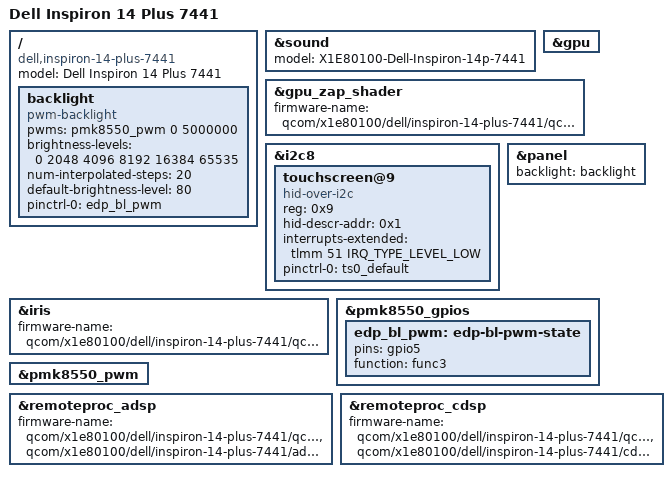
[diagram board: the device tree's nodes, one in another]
// SPDX-License-Identifier: BSD-3-Clause
/*
 * Copyright (c) 2025 Val Packett <val@packett.cool>
 */
/dts-v1/;

#include "hamoa.dtsi"
#include "x1-dell-thena.dtsi"

/ {
	model = "Dell Inspiron 14 Plus 7441";
	compatible = "dell,inspiron-14-plus-7441", "qcom,x1e80100";

	backlight: backlight {
		compatible = "pwm-backlight";
		pwms = <&pmk8550_pwm 0 5000000>;

		brightness-levels = <0 2048 4096 8192 16384 65535>;
		num-interpolated-steps = <20>;
		default-brightness-level = <80>;

		pinctrl-0 = <&edp_bl_pwm>;
		pinctrl-names = "default";
	};
};

&sound {
	model = "X1E80100-Dell-Inspiron-14p-7441";
};

&gpu {
	status = "okay";
};

&gpu_zap_shader {
	firmware-name = "qcom/x1e80100/dell/inspiron-14-plus-7441/qcdxkmsuc8380.mbn";
};

&i2c8 {
	touchscreen@9 {
		compatible = "hid-over-i2c";
		reg = <0x9>;

		hid-descr-addr = <0x1>;
		interrupts-extended = <&tlmm 51 IRQ_TYPE_LEVEL_LOW>;

		pinctrl-0 = <&ts0_default>;
		pinctrl-names = "default";
	};
};

&iris {
	firmware-name = "qcom/x1e80100/dell/inspiron-14-plus-7441/qcvss8380.mbn";
	status = "okay";
};

&panel {
	backlight = <&backlight>;
};

&pmk8550_gpios {
	edp_bl_pwm: edp-bl-pwm-state {
		pins = "gpio5";
		function = "func3";
	};
};

&pmk8550_pwm {
	status = "okay";
};

&remoteproc_adsp {
	firmware-name = "qcom/x1e80100/dell/inspiron-14-plus-7441/qcadsp8380.mbn",
			"qcom/x1e80100/dell/inspiron-14-plus-7441/adsp_dtbs.elf";

	status = "okay";
};

&remoteproc_cdsp {
	firmware-name = "qcom/x1e80100/dell/inspiron-14-plus-7441/qccdsp8380.mbn",
			"qcom/x1e80100/dell/inspiron-14-plus-7441/cdsp_dtbs.elf";

	status = "okay";
};
